# STM32U585xx register map
File version: 1.0
Registers are 32-bit, read-write, reset 0x0 unless marked. A register's access mark holds for its fields unless they carry their own. Offsets are from the block's base; [hi:lo] are bit positions; {n}, {i} and the like mark numbered series; 'fields as' and 'values as' point back to an identical list.

## FMC_Bank3_R — Flexible Memory Controller Bank3
Base 0x420D0480
Same registers: FMC_Bank3_R_S 0x520D0480
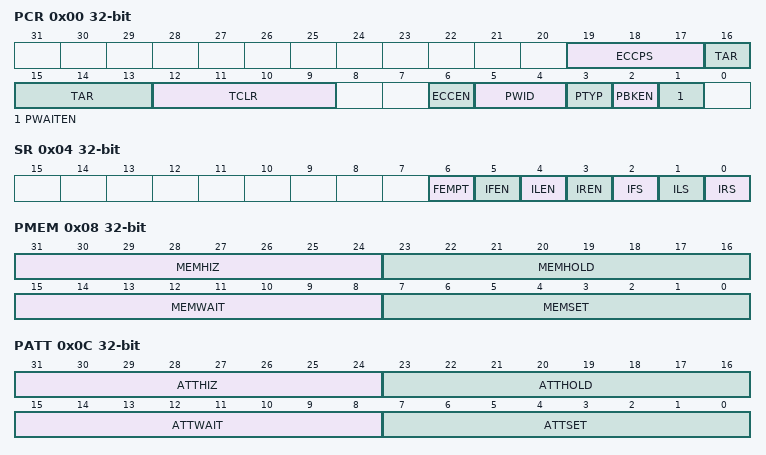
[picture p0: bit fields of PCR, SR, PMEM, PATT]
0x00 PCR — NAND Flash control register
  [19:17] ECCPS — ECCPS[1:0] bits (ECC page size)
  [16:13] TAR — TAR[3:0] bits (ALE to RE delay)
  [12:9] TCLR — TCLR[3:0] bits (CLE to RE delay)
  [6] ECCEN — ECC computation logic enable bit
  [5:4] PWID — PWID[1:0] bits (NAND Flash databus width)
  [3] PTYP — Memory type
  [2] PBKEN — NAND Flash memory bank enable bit
  [1] PWAITEN — Wait feature enable bit
0x04 SR — NAND Flash FIFO status and interrupt register
  [6] FEMPT — FIFO empty
  [5] IFEN — Interrupt Falling Edge detection Enable bit
  [4] ILEN — Interrupt Level detection Enable bit
  [3] IREN — Interrupt Rising Edge detection Enable bit
  [2] IFS — Interrupt Falling Edge status
  [1] ILS — Interrupt Level status
  [0] IRS — Interrupt Rising Edge status
0x08 PMEM — NAND Flash Common memory space timing register
  [31:24] MEMHIZ — MEMHIZ[7:0] bits (Common memory databus HiZ time)
  [23:16] MEMHOLD — MEMHOLD[7:0] bits (Common memory hold time)
  [15:8] MEMWAIT — MEMWAIT[7:0] bits (Common memory wait time)
  [7:0] MEMSET — MEMSET[7:0] bits (Common memory setup time)
0x0C PATT — NAND Flash Attribute memory space timing register
  [31:24] ATTHIZ — ATTHIZ[7:0] bits (Attribute memory databus HiZ time)
  [23:16] ATTHOLD — ATTHOLD[7:0] bits (Attribute memory hold time)
  [15:8] ATTWAIT — ATTWAIT[7:0] bits (Attribute memory wait time)
  [7:0] ATTSET — ATTSET[7:0] bits (Attribute memory setup time)
0x14 ECCR — NAND Flash ECC result registers

## FMC_Bank1E_R — Flexible Memory Controller Bank1E
Base 0x420D0504
Same registers: FMC_Bank1E_R_S 0x520D0504
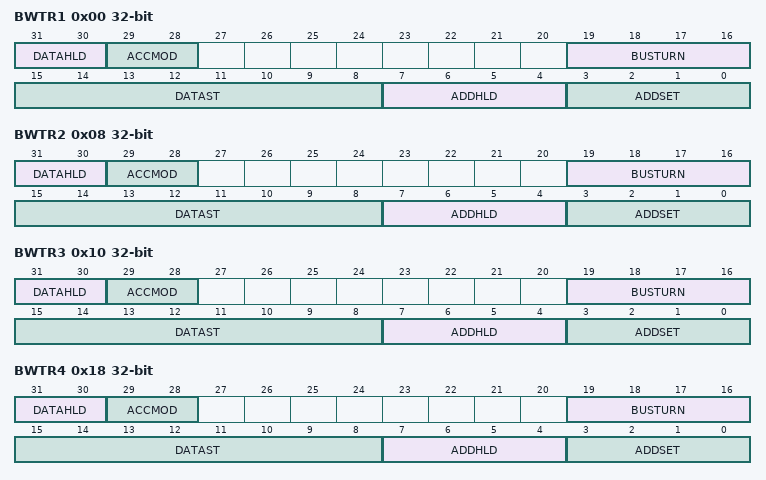
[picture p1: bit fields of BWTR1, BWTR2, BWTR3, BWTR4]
0x00 BWTR1 — NOR/PSRAM write timing registers
  [31:30] DATAHLD — DATAHLD[1:0] bits (Data hold phase duration)
  [29:28] ACCMOD — ACCMOD[1:0] bits (Access mode)
  [19:16] BUSTURN — BUSTURN[3:0] bits (Bus turnaround phase duration)
  [15:8] DATAST — DATAST [3:0] bits (Data-phase duration)
  [7:4] ADDHLD — ADDHLD[3:0] bits (Address-hold phase duration)
  [3:0] ADDSET — ADDSET[3:0] bits (Address setup phase duration)
0x08 BWTR2 — NOR/PSRAM write timing registers
  fields as BWTR1
0x10 BWTR3 — NOR/PSRAM write timing registers
  fields as BWTR1
0x18 BWTR4 — NOR/PSRAM write timing registers
  fields as BWTR1

## SYSCFG — System configuration controller
Base 0x46000400
Same registers: SYSCFG_S 0x56000400
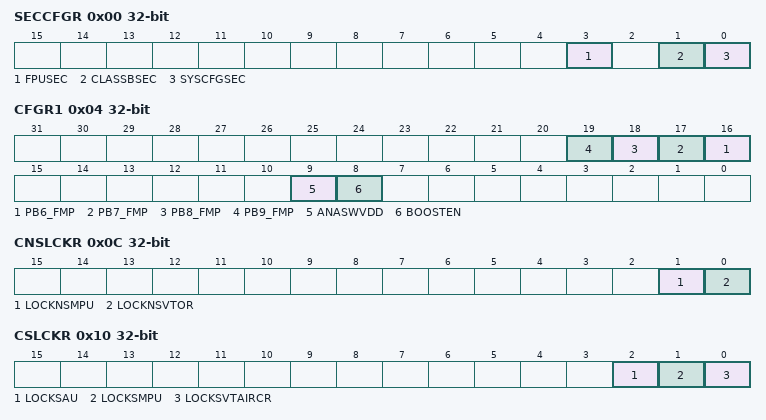
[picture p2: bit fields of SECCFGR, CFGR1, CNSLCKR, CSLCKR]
0x00 SECCFGR — SYSCFG secure configuration register
  [3] FPUSEC — FPU SYSCFG security enable
  [1] CLASSBSEC — ClassB SYSCFG security enable
  [0] SYSCFGSEC — SYSCFG clock control security enable
0x04 CFGR1 — SYSCFG configuration register 1
  [n+10] PB{n}_FMP (n=6..9) — PB{n} Fast mode plus
  [9] ANASWVDD — GPIO analog switch control voltage selection
  [8] BOOSTEN — I/O analog switch voltage booster enable
0x08 FPUIMR — SYSCFG FPU interrupt mask register
  [5:0] FPU_IE — All FPU interrupts enable
0x0C CNSLCKR — SYSCFG CPU non-secure lock register
  [1] LOCKNSMPU — Disable Non-Secure MPU registers writes by SW or debug agent
  [0] LOCKNSVTOR — Disable VTOR_NS register writes by SW or debug agent
0x10 CSLCKR — SYSCFG CPU secure lock register
  [2] LOCKSAU — Disable changes to SAU registers
  [1] LOCKSMPU — Disable changes to the secure MPU registers writes by SW or debug agent
  [0] LOCKSVTAIRCR — Disable changes to the secure vector table address, handling of system faults
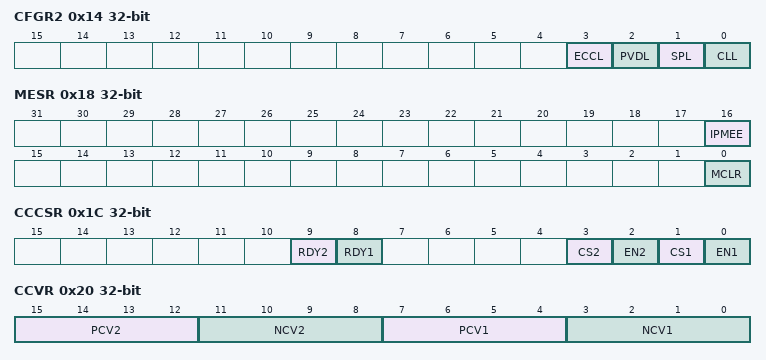
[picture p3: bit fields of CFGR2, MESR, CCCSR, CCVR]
0x14 CFGR2 — SYSCFG configuration register 2
  [3] ECCL — ECC Lock
  [2] PVDL — PVD Lock
  [1] SPL — SRAM ECC Lock
  [0] CLL — Core Lockup Lock
0x18 MESR — SYSCFG Memory Erase Status register
  [16] IPMEE — Status of End of Erase for ICache and PKA RAMs
  [0] MCLR — Status of Erase after Reset
0x1C CCCSR — SYSCFG Conpensaion Cell Control&Status register
  [9] RDY2 — VDDIO compensation cell ready flag
  [8] RDY1 — VDD compensation cell ready flag
  [3] CS2 — Code selection for VDDIO power rail
  [2] EN2 — Enable compensation cell for VDDIO power rail
  [1] CS1 — Code selection for VDD power rail
  [0] EN1 — Enable compensation cell for VDD power rail
0x20 CCVR — SYSCFG Conpensaion Cell value register
  [15:12] PCV2 — PMOS compensation value for VDDIO Power Rail
  [11:8] NCV2 — NMOS compensation value for VDDIO Power Rail
  [7:4] PCV1 — PMOS compensation value for VDD Power Rail
  [3:0] NCV1 — NMOS compensation value for VDD Power Rail
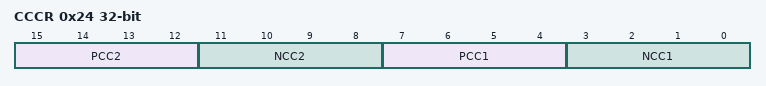
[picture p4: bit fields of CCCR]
0x24 CCCR — SYSCFG Conpensaion Cell Code register
  [15:12] PCC2 — PMOS compensation code for VDDIO Power Rail
  [11:8] NCC2 — NMOS compensation code for VDDIO Power Rail
  [7:4] PCC1 — PMOS compensation code for VDD Power Rail
  [3:0] NCC1 — NMOS compensation code for VDD Power Rail
0x2C RSSCMDR — SYSCFG RSS command mode register
  [15:0] RSSCMD — RSS command
